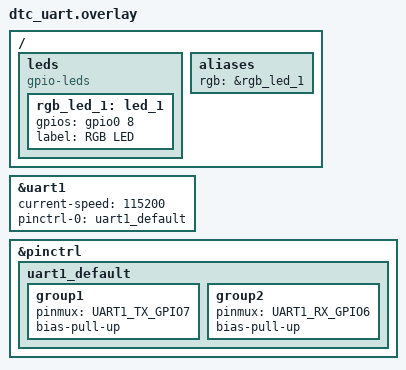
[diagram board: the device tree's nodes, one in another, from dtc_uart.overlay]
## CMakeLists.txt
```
# SPDX-License-Identifier: Apache-2.0

cmake_minimum_required(VERSION 3.20.0)
set(CONF_FILE prj.conf)
set(DTC_OVERLAY_FILE dtc_uart.overlay)

find_package(Zephyr REQUIRED HINTS $ENV{ZEPHYR_BASE})

FILE(GLOB app_sources src/*.c)
target_sources(app PRIVATE ${app_sources}
                            ./src/motordriver.c
                            ./src/rovermotor.c
                            ./src/roveruart.c
                            ./src/pos_mobile_bt.c
                            )
                            

project(Prac2)
```

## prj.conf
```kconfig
CONFIG_I2C=y


# new 
CONFIG_BT=y
#CONFIG_BT_CENTRAL=y
#CONFIG_BT_HOST_CCM=y

CONFIG_SERIAL=y
CONFIG_UART_INTERRUPT_DRIVEN=y
CONFIG_GPIO=y
CONFIG_I2C=y

CONFIG_STDOUT_CONSOLE=n
CONFIG_CBPRINTF_FP_SUPPORT=y

CONFIG_PRINTK=y
CONFIG_SHELL=y
CONFIG_LOG=y
CONFIG_INIT_STACKS=y
CONFIG_THREAD_STACK_INFO=y
CONFIG_KERNEL_SHELL=y
CONFIG_THREAD_MONITOR=y
CONFIG_BOOT_BANNER=n
CONFIG_THREAD_NAME=y
CONFIG_DEVICE_SHELL=y
CONFIG_EVENTS=y 
#CONFIG_POSIX_CLOCK=y
#CONFIG_DATE_SHELL=y
#CONFIG_THREAD_RUNTIME_STATS=y
#CONFIG_THREAD_RUNTIME_STATS_USE_TIMING_FUNCTIONS=y
#CONFIG_STATS=y
#CONFIG_STATS_SHELL=y
#CONFIG_BT_GATT_READ_MULTIPLE=y


CONFIG_NEWLIB_LIBC=y

CONFIG_SYSTEM_WORKQUEUE_STACK_SIZE=4096


#CONFIG_BT_BROADCASTER=y
#CONFIG_BT_OBSERVER=y
CONFIG_BT_GATT_CLIENT=y


# CONFIG_SETTINGS=y
# CONFIG_BT_SETTINGS=y
CONFIG_BT_DEVICE_NAME="rsatsrrast eir"
CONFIG_BT_SMP=y
#CONFIG_BT_MAX_CONN=3
CONFIG_BT_SIGNING=n
CONFIG_BT_PERIPHERAL=y
#CONFIG_BT_DIS=y
#CONFIG_BT_BAS=y
#CONFIG_BT_HRS=y
#CONFIG_BT_IAS=y
#CONFIG_BT_PRIVACY=y
```

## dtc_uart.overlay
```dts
#include <zephyr/dt-bindings/led/led.h>
/ {
	leds {
		compatible = "gpio-leds";
		rgb_led_1: led_1 {
			gpios = <&gpio0 8 GPIO_ACTIVE_HIGH>;
			label = "RGB LED";
		};
	};
	aliases {
		rgb = &rgb_led_1;
	};
};

&uart1 {
	status = "okay";
	current-speed = <115200>;
	pinctrl-0 = <&uart1_default>;
	pinctrl-names = "default";
};

&pinctrl {
	uart1_default: uart1_default {
		group1 {
			pinmux = <UART1_TX_GPIO7>;
			bias-pull-up; 
		};
		group2 {
			pinmux = <UART1_RX_GPIO6>;
			bias-pull-up;
		};
	};
};
```

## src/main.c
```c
#include <stdlib.h>

#include <zephyr/kernel.h>
#include <zephyr/logging/log.h>
#include <zephyr/device.h>
#include <zephyr/shell/shell.h>
#include <zephyr/drivers/i2c.h>
#include <zephyr/drivers/uart.h>
#include "rovermotor.h"
#include "roveruart.h"
#include "ahu_rgb.h"
#include <math.h> 
#include "pos_mobile_bt.h"
#define LOG_LEVEL 4
LOG_MODULE_REGISTER(main);

// RGB thread stack
K_THREAD_STACK_DEFINE(ahu_rgb_stack, AHU_RGB_STACK_SIZE);
struct k_thread ahu_rgb_thread_data;

//  Global to pass to shell commands. 
struct rovermotor_info motor_control_handle; 
struct roveruart_info uart_control_handle; 
const struct device* i2c_dev = DEVICE_DT_GET(DT_NODELABEL(i2c0));
const struct device* uart_dev = DEVICE_DT_GET(DT_NODELABEL(uart1));

// Helper function definition
void send_ahu_rgb(uint8_t red, uint8_t green, uint8_t blue);
void send_pos_to_bt_thread(struct k_msgq* pos_msgq, struct pos_data* position_bt) ;
void update_motor_and_rgb(
	uint8_t left_pedal, 
	uint8_t right_pedal, 
	uint8_t rudder_angle, 
	struct rovermotor_info* motor_handle);


/** 
 * Diagnostic command callback 
 */
static int rgb_cmd_callback(const struct shell* shell, size_t argc, char** argv)
{
	/* Struct to send rgb control information to the ahu rgb thread */
	struct ahu_rgb_colour colour;
	int r = atoi(argv[1]);
	int g = atoi(argv[2]);
	int b = atoi(argv[3]);

	if (r >= 0 && g >= 0 && b >= 0
			&& r < 256 && g < 256 && b < 256) {
		shell_fprintf(shell, SHELL_NORMAL,
				"writing rgb <%d,%d,%d>\n", r, g, b);
		send_ahu_rgb(r, g, b);
	} else {
		shell_fprintf(shell, SHELL_ERROR,
				"invalid rgb, 0 <= rgb values <= 255\n");
	}

	return 0;
}


/** 
 * Diagnostic command callback
 */
static int rover_cmd_cb(const struct shell* shell, size_t argc, char** argv) 
{
	int8_t vel = atoi(argv[1]); 
	int angle_percent = atoi(argv[2]); 
	float angle = ((float) (angle_percent)) / 100; 
	//LOG_INF("Commanding speed: %hhi, angle: %f", vel, angle);
	LOG_ERR("Deprecated");
	//update_motor_and_rgb(vel, angle, &motor_control_handle); 
	return 0;
}


/** 
 * Abstraction to handle setting motor turn rate and forward speed based on 
 * pedal position and 'angle' 
 */
void update_motor_and_rgb(
	uint8_t left_pedal, 
	uint8_t right_pedal, 
	uint8_t rudder_angle, 
	struct rovermotor_info* motor_handle) 
{
	// Convert 0 <= X <= 180 to -1 <= y <= +1 for rotation rate target. 
	int8_t rudder_centred_at_zero = ((int8_t) (rudder_angle)) - 90; 
	float angle_command = ((float)  (rudder_centred_at_zero)) / 90; 
	// Consider velocity forwards as difference between right and left pedal. 
	// Offset so full left pedal zero right is full reverse. 
	int8_t fwd_vel = ((int) (right_pedal) - (int) (left_pedal));
	rovermotor_send_instruction(motor_handle, angle_command, fwd_vel);

	int8_t r = fwd_vel + 127; 
	int8_t b = (255 - r);
	int8_t g = (int8_t) (angle_command * 128) + 127; 
	send_ahu_rgb(r, g, b); 
}

static int reset_angle_cmd_cb(const struct shell* shell, size_t argc, char** argv) 
{
	roveruart_reset_angle(&uart_control_handle);
	LOG_INF("Resetting angle");
	return 0;
}
#define STACKSIZE 1024
#define PRIORITY 7
#define MSG_SIZE 32
K_THREAD_DEFINE(ble_id, STACKSIZE * 4, ble_connect_main, NULL, NULL, NULL,
		PRIORITY, 0, 0);

int main(void) 
{
    //int err = bt_enable(NULL);

	/* Create a thread to control the ahu rgb led */
	k_tid_t ahu_rgb_thread_id = k_thread_create(&ahu_rgb_thread_data,
													ahu_rgb_stack,
													AHU_RGB_STACK_SIZE,
													ahu_rgb_thread,
													NULL, NULL, NULL,
													AHU_RGB_PRIORITY,
													0, K_NO_WAIT);

	rovermotor_init(0x5D, 0x5E, i2c_dev, &motor_control_handle); 
	roveruart_init(uart_dev, &uart_control_handle); 
	// LOG_INF("Initialized motor handler");

	/* Diagnostic shell commands */
	SHELL_CMD_ARG_REGISTER(
		rgb,
		NULL,
		"rgb <r> <g> <b>",
		rgb_cmd_callback,
		4,
		0
	);

	SHELL_CMD_ARG_REGISTER(
        rover,
        NULL,
        "rover [speed] [angle]: set speed and angle \n"
		"speed from -127 to 127, angle from -100 to 100 (int)",
        rover_cmd_cb,
        3,
        0
    );
	SHELL_CMD_ARG_REGISTER(
        reset_angle,
        NULL,
        "Reset angle refernce\n",
		reset_angle_cmd_cb,
        0,
        0
    );
	rover_position_info_t position;

	/* Struct to send rgb control information to the ahu rgb thread */
	struct ahu_rgb_colour rgb_colour;

	/* Struct to send position data to the bt thread */
	struct pos_data position_bt;

	/* Struct to receive control data from the bt thread */
	struct control_data control;
	int res = 0;
	k_msleep(50);
	roveruart_reset_angle(&uart_control_handle);
	while (1)
	{
		k_sleep(K_MSEC(200));
		// Does not wait for new values to publish. 
		res = roveruart_get_new_position(&uart_control_handle, &position);
		if (res) {
			// Nothing pending to send back. 
		} else {
			LOG_INF("Got position: (%hhu, %hhu)", position.x, position.y); 

			// Only send position data if we recieve it. 
			position_bt.x_pos = position.x;
			position_bt.y_pos = position.y;
			send_pos_to_bt_thread(&pos_msgq, &position_bt);
		}

        /* Check if update reference angle semaphore has been given from UART thread */
        if (!k_sem_take(&update_ref_angle_sem, K_NO_WAIT)) {
			roveruart_reset_angle(&uart_control_handle);
			LOG_INF("Resetting angle");
        }

		/* Check for control data from bt thread */
		if (!k_msgq_get(&control_msgq, &control, K_NO_WAIT)) {
			LOG_INF("Received from pedals: %d, %d, %d\n", control.pedal_left, control.pedal_right, control.rudder_angle);

			// Assumptions: 
			// -90 <= RUDDER < 90. 
			// pedal left and right fully saturate uint8_t range 0-255. 
			update_motor_and_rgb(
				control.pedal_left, 
				control.pedal_right, 
				control.rudder_angle, 
				&motor_control_handle);
		}
	}
}

/**
 * Sends position to BT thread (see: pos_mobile_bt.c) to be transmitted
 * to base node. Purges queue and does not send if queue is full. Non-blocking
 */
void send_pos_to_bt_thread(struct k_msgq* pos_msgq, struct pos_data* position_bt) 
{
	/* Send position data to bt thread */
	if (k_msgq_put(pos_msgq, position_bt, K_NO_WAIT) != 0) {
		/* Queue is full, purge it */
		k_msgq_purge(pos_msgq);
	}
}

/* Send the given rgb value to the ahu rgb led */
void send_ahu_rgb(uint8_t red, uint8_t green, uint8_t blue)
{
	/* Struct to send rgb control information to the ahu rgb thread */
	struct ahu_rgb_colour colour;
	colour.red = red;
	colour.green = green;
	colour.blue = blue;

	/* Send rgb control struct to rgb message queue */
	if (k_msgq_put(&ahu_rgb_msgq, &colour, K_NO_WAIT) != 0) {
		/* Queue is full, purge it */
		k_msgq_purge(&ahu_rgb_msgq);
	}
}
```

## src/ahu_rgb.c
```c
#include "ahu_rgb.h"

/*
Defining private macro functions to write a '1' or a '0' to
the specified gpio register and pin. Based on macros defined in ahu_rgb.h
*/
#define ONE_BIT(reg, pin) do { \
	__asm volatile (SET_HIGH \
			DELAY_T1H \
			SET_LOW \
			DELAY_T1L \
			:: \
			[out_reg] "r" (reg), \
			[gpio_pin] "i" (pin)); } while (false)

#define ZERO_BIT(reg, pin) do { \
	__asm volatile (SET_HIGH \
			DELAY_T0H \
			SET_LOW \
			DELAY_T0L \
			:: \
			[out_reg] "r" (reg), \
			[gpio_pin] "i" (pin)); } while (false)

/* colour as an uint32_t (using the first 24 bits) in the order of GRB */
#define WRITE_RGB(reg, pin, colour) do { \
	__asm__ volatile ( \
			"li t2, 0x1000000\n\t" \
			"loop_start: srli t2, t2, 1\n\t" \
			"bnez t2, bit_high\n\t" \
			"j loop_end\n\t" \
			"bit_high: and t3, %[rgb_value], t2\n\t" \
			"beqz t3, bit_low\n\t" \
			SET_HIGH DELAY_T1H SET_LOW DELAY_T1L \
			"j loop_start\n\t" \
			"bit_low: " SET_HIGH DELAY_T0H SET_LOW DELAY_T0L \
			"j loop_start\n\t" \
			"loop_end: " \
			:: \
			[out_reg] "r" (reg), \
			[gpio_pin] "i" (pin), \
			[rgb_value] "r" (colour) \
			: "t0", "t1", "t2", "t3", "memory" \
		); \
	} while (false)

/* Initialising message queue to be used by ahu rgb thread */
K_MSGQ_DEFINE(
    ahu_rgb_msgq,
    sizeof(struct ahu_rgb_colour),
    AHU_RGB_MSGQ_MAX_MSG,
    AHU_RGB_MSGQ_ALIGN
);

/* Function definition */
void send_rgb(uint8_t red, uint8_t green, uint8_t blue);


/* The devicetree node identifier for the "rgb_led" alias. */
#define RGB_LED_NODE DT_ALIAS(rgb)

/* Get GPIO pin information from devicetree */
static const struct gpio_dt_spec rgb = GPIO_DT_SPEC_GET(RGB_LED_NODE, gpios);

void ahu_rgb_thread(void *, void *, void *)
{
    /* Ensure that the GPIO pin for rgb control is ready */
	if (!gpio_is_ready_dt(&rgb)) {
		return;
	}

    /* Initialise the GPIO pin to be logic level low */
    gpio_pin_configure_dt(&rgb, GPIO_OUTPUT_INACTIVE);

	/* Ensure rgb gpio low */
	gpio_pin_set_dt(&rgb, 0);

    /* Struct to receive ahu rgb control data */
    struct ahu_rgb_colour colour;
	colour.red=0; colour.green=0; colour.blue=0;

    while (1) {
        /* Check message queue for rgb control structs */
        k_msgq_get(&ahu_rgb_msgq, &colour, K_NO_WAIT);

		send_rgb(0, 0, 0);
		send_rgb(colour.red, colour.green, colour.blue);

        /* Sleep for 500ms */
        k_msleep(500);

    }

}

/* Helper function to send rgb values to the addressable led */
void send_rgb(uint8_t red, uint8_t green, uint8_t blue)
{
	/* Retrieve gpio output register and gpio pin */
	volatile uint32_t *out_reg = (uint32_t *)RGB_GPIO_REG;
	const uint32_t gpio_pin = (uint32_t)RGB_GPIO_PIN;

	/* Create a byte array to store the rgb colour in the
		correct order (GRB) */
	uint8_t colour_buf[NUM_COLOURS];
	colour_buf[0] = green;
	colour_buf[1] = red;
	colour_buf[2] = blue;
	uint8_t *p_colour_buf = colour_buf;

	/* Disable interrupts and preemption */
	k_sched_lock();
	unsigned int key = irq_lock();

	/* Loop through three colours */
	for (int i = 0; i < NUM_COLOURS; i++) {
		
		uint32_t b = *p_colour_buf++;

		for (int32_t j = 7; j >= 0; j--) {
			if (b & BIT(j)) {
				ONE_BIT(out_reg, gpio_pin);
			} else {
				ZERO_BIT(out_reg, gpio_pin);
			}
		}

	}

	/* Re-enable interrupts and preemption */
	irq_unlock(key);
	k_sched_unlock();

    /* Reset delay to ensure LED latches */
	k_busy_wait(RGB_RESET_DELAY_US);

}
```

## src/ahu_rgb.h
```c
#ifndef AHU_RGB_H_
#define AHU_RGB_H_

#include <zephyr/kernel.h>
#include <zephyr/drivers/gpio.h>
#include <string.h>

/* Defining macros for nop assembly instructions */
#define NOP1 "nop\n\t"
#define NOP2 NOP1 NOP1
#define NOP4 NOP2 NOP2
#define NOP8 NOP4 NOP4
#define NOP16 NOP8 NOP8
#define NOP32 NOP16 NOP16
#define NOP64 NOP32 NOP32
#define NOP128 NOP64 NOP64

/*
Defining macros for the rgb delays (T0H, T1H, T0L, T0H)

Note that system clock is running at 160MHz and
each nop instruction takes one clock cycle to complete
=> each nop has a delay of 1/160Mhz = 6.25ns

Based on timings for the SK6812 RGB LED:

T0H: 300ns/6.25ns = 48 cycles = 32+16 cycles
T1H: 600ns/6.25ns = 96 cycles = 64+32 cycles
T0L: 900ns/6.25ns = 144 cycles = 128+16 cycles
T1L: 600ns/6.25ns = 96 cycles = 64+32 cycles
*/
#define DELAY_T0H NOP32 NOP16
#define DELAY_T1H NOP64 NOP32
#define DELAY_T0L NOP128 NOP16
#define DELAY_T1L NOP64 NOP32

/* Defining macros with RISC-V assembly to drive specified
   GPIOs high or low */
#define SET_HIGH 	"li t0, 1\n\t" \
					"slli t0, t0, %[gpio_pin]\n\t" \
					"lw t1, 0(%[out_reg])\n\t" \
					"or t1, t1, t0\n\t" \
					"sw t1, 0(%[out_reg])\n\t"

#define SET_LOW 	"li t0, 1\n\t" \
					"slli t0, t0, %[gpio_pin]\n\t" \
					"not t0, t0\n\t" \
					"lw t1, 0(%[out_reg])\n\t" \
					"and t1, t1, t0\n\t" \
					"sw t1, 0(%[out_reg])\n\t"

/* Defining macros for constants */
#define NUM_COLOURS 3
#define RGB_RESET_DELAY_US 80
#define RGB_GPIO_REG 0x60004004
#define RGB_GPIO_PIN 8

/* Macro definitions for ahu rgb thread */
#define AHU_RGB_STACK_SIZE 1024
#define AHU_RGB_PRIORITY 3

/* Macro definitions for ahu rgb control message queue */
#define AHU_RGB_MSGQ_MAX_MSG 10
#define AHU_RGB_MSGQ_ALIGN 4

/* Entry point to ahu rgb thread */
extern void ahu_rgb_thread(void *, void *, void *);

/* struct to control the colour of the ahu rgb */
struct ahu_rgb_colour {
    uint8_t red;
	uint8_t green;
	uint8_t blue;
};

/* Message queue for ahu rgb control */
extern struct k_msgq ahu_rgb_msgq;

#endif
```

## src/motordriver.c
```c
#include "motordriver.h"
LOG_MODULE_REGISTER(motordriver);

/**
 * initializes an instance of a driver for the Sparkfun Qwiic Motor Driver /
 * Sparkfun SCMD motor driver, on given uart device, with given device address
 * @param dev: zephyr i2c device
 * @param device_addr: i2c address of qwiic motor driver. 
 */
void motordriver_init(const struct device* dev, uint8_t device_addr) 
{

    if (!device_is_ready(dev)) {
		LOG_ERR("I2C: Device is not ready.\n");
		return;
	}
    // dummy read - check the device we expect is on this bus. 
    uint8_t res;
    int status = i2c_reg_read_byte(dev, device_addr, SCMD_ID, &res);
    int num_tries = 0; 
    while (res != ID_WORD) 
    {
        LOG_INF("Couldn't get valid ID yet ... ");
        // Keep trying - it might come online. 
        k_sleep(K_MSEC(100));
        status = i2c_reg_read_byte(dev, device_addr, SCMD_ID, &res);
        if (num_tries++ > CONN_MAX_NUM_TRIES) {
            LOG_ERR("Couldn't find driver with addr %x", device_addr);
            return; 
        };

    }
    if (status) {
        LOG_ERR("Dummy read failed");
        // The driver did not come online - ignore for now. 
    } else {
        LOG_INF("Found motor driver with id %x", res);
    }

    // Enable, check enable byte. Bridge left and right channels. 
    i2c_reg_write_byte(dev, device_addr, SCMD_DRIVER_ENABLE, 0x01);

    i2c_reg_read_byte(dev, device_addr, SCMD_DRIVER_ENABLE, &res);
    i2c_reg_write_byte(dev, device_addr, SCMD_BRIDGE, 0x01);
    
    // Zero the motors (in case the driver was left powere)
    motordriver_send_pwm(dev, device_addr, ZERO_SIGNAL); 
}


/** 
 * Sends a value for motor pwm to the motor controller with given i2c addr
 * @param dev: zephyr i2c device
 * @param device_addr: qwiic motor driver i2c address
 * @param val: value to send.
 */
int motordriver_send_pwm(const struct device* dev, uint8_t device_addr, uint8_t val)
{
    //LOG_INF("Motors: %hhu", val);
    int res = i2c_reg_write_byte(dev, device_addr, SCMD_MA_DRIVE, val);
    if (res) {
        return res;
    }
    res = i2c_reg_write_byte(dev, device_addr, SCMD_MB_DRIVE, val);
    return res;
    
}
```

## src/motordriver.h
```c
#ifndef _MOTOR_DRIVER_H_
#define _MOTOR_DRIVER_H_
#include <zephyr/logging/log.h>
#include <zephyr/device.h>
#include <zephyr/drivers/i2c.h>

// Sourced from Sparkfun SCMD driver, original header below: 
/******************************************************************************
SCMD_config.h
Serial Controlled Motor Driver
Marshall Taylor @ SparkFun Electronics
Nov 3, 2016
https://github.com/sparkfun/Serial_Controlled_Motor_Driver
https://github.com/sparkfun/SparkFun_Serial_Controlled_Motor_Driver_Arduino_Library

This file contains common names for memory locations and hardware defaults.
This is used by the PSoC firmware and with the user Arduino library for use in
conjunction with readRegister() and writeRegister().

This code is released under the [MIT License](http://opensource.org/licenses/MIT).
Please review the LICENSE.md file included with this example. If you have any questions 
or concerns with licensing, please contact techsupport@sparkfun.com.
Distributed as-is; no warranty is given.
******************************************************************************/

//defaults ( Set config in PSoC, use for reference in Arduino )   
#define ID_WORD                    0xA9  //Device ID to be programmed into memory for reads
#define START_SLAVE_ADDR           0x50  //Start address of slaves
#define MAX_SLAVE_ADDR             0x5F  //Max address of slaves
#define MASTER_LOCK_KEY            0x9B
#define USER_LOCK_KEY              0x5C
#define FIRMWARE_VERSION           0x07
#define POLL_ADDRESS               0x4A  //Address of an unasigned, ready slave
#define MAX_POLL_LIMIT             0xC8  //200

//SCMD_STATUS_1 bits
#define SCMD_ENUMERATION_BIT       0x01
#define SCMD_BUSY_BIT              0x02
#define SCMD_REM_READ_BIT          0x04
#define SCMD_REM_WRITE_BIT         0x08
#define SCMD_HW_EN_BIT             0x10
 
//SCMD_CONTROL_1 bits
#define SCMD_FULL_RESET_BIT        0x01
#define SCMD_RE_ENUMERATE_BIT      0x02
    
//SCMD_FSAFE_CTRL bits and masks
#define SCMD_FSAFE_DRIVE_KILL      0x01
#define SCMD_FSAFE_RESTART_MASK    0x06
	#define SCMD_FSAFE_REBOOT          0x02
	#define SCMD_FSAFE_RE_ENUM         0x04
#define SCMD_FSAFE_CYCLE_USER      0x08
#define SCMD_FSAFE_CYCLE_EXP       0x10

//SCMD_MST_E_IN_FN bits and masks
#define SCMD_M_IN_RESTART_MASK    0x03
	#define SCMD_M_IN_REBOOT          0x01
	#define SCMD_M_IN_RE_ENUM         0x02
#define SCMD_M_IN_CYCLE_USER      0x04
#define SCMD_M_IN_CYCLE_EXP       0x08

//Address map
#define SCMD_FID                   0x00
#define SCMD_ID                    0x01
#define SCMD_SLAVE_ADDR            0x02
#define SCMD_CONFIG_BITS           0x03
#define SCMD_U_I2C_RD_ERR          0x04
#define SCMD_U_I2C_WR_ERR          0x05
#define SCMD_U_BUF_DUMPED          0x06
#define SCMD_E_I2C_RD_ERR          0x07
#define SCMD_E_I2C_WR_ERR          0x08
#define SCMD_LOOP_TIME	           0x09
#define SCMD_SLV_POLL_CNT          0x0A
#define SCMD_SLV_TOP_ADDR          0x0B
#define SCMD_MST_E_ERR             0x0C
#define SCMD_MST_E_STATUS          0x0D
#define SCMD_FSAFE_FAULTS          0x0E
#define SCMD_REG_OOR_CNT           0x0F
#define SCMD_REG_RO_WRITE_CNT      0x10
#define SCMD_GEN_TEST_WORD         0x11
#define SCMD_MOTOR_A_INVERT        0x12
#define SCMD_MOTOR_B_INVERT        0x13
#define SCMD_BRIDGE                0x14
#define SCMD_LOCAL_MASTER_LOCK     0x15
#define SCMD_LOCAL_USER_LOCK       0x16
#define SCMD_MST_E_IN_FN           0x17
#define SCMD_U_PORT_CLKDIV_U       0x18
#define SCMD_U_PORT_CLKDIV_L       0x19
#define SCMD_U_PORT_CLKDIV_CTRL    0x1A
#define SCMD_E_PORT_CLKDIV_U       0x1B
#define SCMD_E_PORT_CLKDIV_L       0x1C
#define SCMD_E_PORT_CLKDIV_CTRL    0x1D
#define SCMD_U_BUS_UART_BAUD       0x1E
#define SCMD_FSAFE_CTRL            0x1F
#define SCMD_MA_DRIVE              0x20
#define SCMD_MB_DRIVE              0x21
#define SCMD_S1A_DRIVE             0x22
#define SCMD_S1B_DRIVE             0x23
#define SCMD_S2A_DRIVE             0x24
#define SCMD_S2B_DRIVE             0x25
#define SCMD_S3A_DRIVE             0x26
#define SCMD_S3B_DRIVE             0x27
#define SCMD_S4A_DRIVE             0x28
#define SCMD_S4B_DRIVE             0x29
#define SCMD_S5A_DRIVE             0x2A
#define SCMD_S5B_DRIVE             0x2B
#define SCMD_S6A_DRIVE             0x2C
#define SCMD_S6B_DRIVE             0x2D
#define SCMD_S7A_DRIVE             0x2E
#define SCMD_S7B_DRIVE             0x2F
#define SCMD_S8A_DRIVE             0x30
#define SCMD_S8B_DRIVE             0x31
#define SCMD_S9A_DRIVE             0x32
#define SCMD_S9B_DRIVE             0x33
#define SCMD_S10A_DRIVE            0x34
#define SCMD_S10B_DRIVE            0x35
#define SCMD_S11A_DRIVE            0x36
#define SCMD_S11B_DRIVE            0x37
#define SCMD_S12A_DRIVE            0x38
#define SCMD_S12B_DRIVE            0x39
#define SCMD_S13A_DRIVE            0x3A
#define SCMD_S13B_DRIVE            0x3B
#define SCMD_S14A_DRIVE            0x3C
#define SCMD_S14B_DRIVE            0x3D
#define SCMD_S15A_DRIVE            0x3E
#define SCMD_S15B_DRIVE            0x3F
#define SCMD_S16A_DRIVE            0x40
#define SCMD_S16B_DRIVE            0x41

#define SCMD_INV_2_9               0x50
#define SCMD_INV_10_17             0x51
#define SCMD_INV_18_25             0x52
#define SCMD_INV_26_33             0x53
#define SCMD_BRIDGE_SLV_L          0x54
#define SCMD_BRIDGE_SLV_H          0x55

#define SCMD_DRIVER_ENABLE         0x70
#define SCMD_UPDATE_RATE           0x71
#define SCMD_FORCE_UPDATE          0x72
#define SCMD_E_BUS_SPEED           0x73
#define SCMD_MASTER_LOCK           0x74
#define SCMD_USER_LOCK             0x75
#define SCMD_FSAFE_TIME            0x76
#define SCMD_STATUS_1              0x77
#define SCMD_CONTROL_1             0x78

#define SCMD_REM_ADDR              0x79
#define SCMD_REM_OFFSET            0x7A
#define SCMD_REM_DATA_WR           0x7B
#define SCMD_REM_DATA_RD           0x7C
#define SCMD_REM_WRITE             0x7D
#define SCMD_REM_READ              0x7E

#define CONN_MAX_NUM_TRIES 5

#define ZERO_SIGNAL 127 


/**
 * initializes an instance of a driver for the Sparkfun Qwiic Motor Driver /
 * Sparkfun SCMD motor driver, on given uart device, with given device address
 * @param dev: zephyr i2c device
 * @param device_addr: i2c address of qwiic motor driver. 
 */
extern void motordriver_init(const struct device* dev, uint8_t device_addr);


/** 
 * Sends a value for motor pwm to the motor controller with given i2c addr
 * @param dev: zephyr i2c device
 * @param device_addr: qwiic motor driver i2c address
 * @param val: value to send.
 */
extern int motordriver_send_pwm(const struct device* dev, uint8_t device_addr, uint8_t val); 

#endif 
```

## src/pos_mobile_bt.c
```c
#include "pos_mobile_bt.h"

#ifdef CONFIG_ARCH_POSIX
#include <unistd.h>
#else
#include <zephyr/posix/unistd.h>
#endif

/* Initialising message queue for control data */
K_MSGQ_DEFINE(
    control_msgq,
    sizeof(struct control_data),
    CONTROL_MSGQ_MAX_MSG,
    CONTROL_MSGQ_ALIGN
);

/* Initialising message queue for position data */
K_MSGQ_DEFINE(
    pos_msgq,
    sizeof(struct pos_data),
    POS_MSGQ_MAX_MSG,
    POS_MSGQ_ALIGN
);

/* Semaphore to signal refernce angle updates */
K_SEM_DEFINE(update_ref_angle_sem, 0, 1);

static struct bt_conn *default_conn;
bool bt_connected;

LOG_MODULE_REGISTER(app);

uint8_t current_cont[] = {0, 90, 0};
uint8_t pos_data[] = {0, 0};

static const struct bt_data ad[] = {
    BT_DATA_BYTES(BT_DATA_FLAGS, (BT_LE_AD_GENERAL | BT_LE_AD_NO_BREDR)),
    BT_DATA_BYTES(BT_DATA_UUID128_ALL,
                  0xd0, 0x92, 0x67, 0x35, 0x78, 0x16, 0x21, 0x91,
                  0x26, 0x49, 0x60, 0xeb, 0x06, 0xa7, 0xca, 0xcb),
};

static struct bt_uuid_128 mobile_uuid = BT_UUID_INIT_128(
    0xd0, 0x92, 0x67, 0x35, 0x78, 0x16, 0x21, 0x91,
    0x26, 0x49, 0x60, 0xeb, 0x06, 0xa7, 0xca, 0xcb);

static struct bt_uuid_128 pos_uuid = BT_UUID_INIT_128(
    0xd8, 0x92, 0x67, 0x35, 0x78, 0x16, 0x21, 0x91,
    0x26, 0x49, 0x60, 0xeb, 0x06, 0xa7, 0xca, 0xcb);

static struct bt_uuid_128 cont_uuid = BT_UUID_INIT_128(
    0xd8, 0x92, 0x67, 0x35, 0x78, 0x16, 0xa1, 0x91,
    0x26, 0x29, 0x60, 0xeb, 0x46, 0xa7, 0xca, 0xcb);

static struct bt_uuid_128 angle_uuid = BT_UUID_INIT_128(
    0xd8, 0x92, 0x67, 0x35, 0x50, 0x16, 0x21, 0x91,
    0x26, 0x49, 0x06, 0xeb, 0x06, 0xa7, 0x23, 0xcb);


static ssize_t give_pos(struct bt_conn *conn,
                          const struct bt_gatt_attr *attr, void *buf,
                          uint16_t len, uint16_t offset)
{
    const int16_t *value = attr->user_data;

    return bt_gatt_attr_read(conn, attr, buf, len, offset, value, sizeof(pos_data));
}

static ssize_t update_angle(struct bt_conn *conn,
                          const struct bt_gatt_attr *attr, void *buf,
                          uint16_t len, uint16_t offset)
{
    const int16_t *value = NULL;
    
    /* Send semaphore to main */
    k_sem_give(&update_ref_angle_sem);
    LOG_ERR("sending semaphore");

    return bt_gatt_attr_read(conn, attr, buf, len, offset, value, 0);
}

BT_GATT_SERVICE_DEFINE(mobile_svc,
                       BT_GATT_PRIMARY_SERVICE(&mobile_uuid),
                       
                       BT_GATT_CHARACTERISTIC(&pos_uuid.uuid,
                                              BT_GATT_CHRC_READ,
                                              BT_GATT_PERM_READ,
                                              give_pos, NULL, &pos_data),

                       BT_GATT_CHARACTERISTIC(&angle_uuid.uuid,
                                              BT_GATT_CHRC_READ,
                                              BT_GATT_PERM_READ,
                                              update_angle, NULL, NULL),  );


static void connected(struct bt_conn *conn, uint8_t err)
{
    if (err) {
		LOG_ERR("Connection failed (err 0x%02x)\n", err);
        bt_connected = false;
	} else {
		LOG_INF("Connected");
        bt_connected = true;
	}
    default_conn = conn;
}

static void disconnected(struct bt_conn *conn, uint8_t reason)
{
    LOG_INF("Disconnected");
	bt_connected = false;
}

static void auth_passkey_display(struct bt_conn *conn, unsigned int passkey)
{
    char addr[BT_ADDR_LE_STR_LEN];

    bt_addr_le_to_str(bt_conn_get_dst(conn), addr, sizeof(addr));

}

static void auth_cancel(struct bt_conn *conn)
{
    char addr[BT_ADDR_LE_STR_LEN];

    bt_addr_le_to_str(bt_conn_get_dst(conn), addr, sizeof(addr));
	k_msleep(50);
}

uint8_t read_cont(struct bt_conn *conn, uint8_t err,
                               struct bt_gatt_read_params *params,
                               const void *data, uint16_t length)
{
    if (length == 3 && bt_connected) {
        memcpy(&current_cont, data, 3);
        //printk("%d %d %d\n", current_cont[0], current_cont[1], current_cont[2]);
    }
    return 0;
}


static struct bt_conn_cb conn_callbacks = {
    .connected = connected,
    .disconnected = disconnected,
};

static struct bt_conn_auth_cb auth_cb_display = {
    .passkey_display = auth_passkey_display,
    .passkey_entry = NULL,
    .cancel = auth_cancel,
};

static void bt_ready(void)
{
    int err = 0;
    err = bt_enable(NULL);
    if (err)
    {
        printk("Bluetooth init failed (err %d)\n", err);
        return;
    }

    printk("Bluetooth initialized\n");
    /*
    if (IS_ENABLED(CONFIG_SETTINGS))
    {
        settings_load();
    }
    */
    err = bt_le_adv_start(BT_LE_ADV_CONN_NAME, ad, ARRAY_SIZE(ad), NULL, 0);

    if (err)
    {
        printk("Advertising failed to start (err %d)\n", err);
        return;
    }
    printk("Advertising successfully started\n");
}

void ble_connect_main(void)
{
	bt_ready();

    bt_conn_cb_register(&conn_callbacks);
    bt_conn_auth_cb_register(&auth_cb_display);

    static struct bt_gatt_read_params read_cont_params = {
        .func = read_cont,
        .handle_count = 0,
        .by_uuid.uuid = &cont_uuid.uuid,
        .by_uuid.start_handle = BT_ATT_FIRST_ATTRIBUTE_HANDLE,
        .by_uuid.end_handle = BT_ATT_LAST_ATTRIBUTE_HANDLE,
    };

    /* Struct to store all control values */
    struct control_data control;

    /* Struct to store position values */
    struct pos_data position;

    while (1)
    {
        if (bt_connected) {
            bt_gatt_read(default_conn, &read_cont_params);

            control.pedal_left = current_cont[0];
            control.pedal_right = current_cont[1];
            control.rudder_angle = current_cont[2];

            /* Send control data to main */
            //LOG_INF("Sending to main");
            if (k_msgq_put(&control_msgq, &control, K_NO_WAIT) != 0) {
                /* Queue is full, purge it */
                LOG_ERR("Purging control message queue to main. ");
                k_msgq_purge(&control_msgq);
            }

            // Check for updated pos from main
            while (!k_msgq_get(&pos_msgq, &position, K_MSEC(200))) {
                pos_data[0] = position.x_pos;
                pos_data[1] = position.y_pos;
            }

        } else {
            k_msleep(100);
        }
    }
}
```

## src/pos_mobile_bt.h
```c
#ifndef BSU_BT_H
#define BSU_BT_H

#include <zephyr/kernel.h>

#include <zephyr/types.h>

#include <zephyr/sys/printk.h>
#include <zephyr/sys/byteorder.h>
#include <zephyr/sys/util.h>

#include <zephyr/shell/shell.h>

#include <zephyr/drivers/uart.h>
#include <zephyr/drivers/gpio.h>
#include <zephyr/devicetree.h>

#include <zephyr/logging/log.h>

#include <zephyr/bluetooth/bluetooth.h>
#include <zephyr/bluetooth/hci.h>
#include <zephyr/bluetooth/conn.h>
#include <zephyr/bluetooth/uuid.h>
#include <zephyr/bluetooth/gatt.h>

#include <stddef.h>
#include <errno.h>
#include <version.h>
#include <stdlib.h>
#include <ctype.h>
#include <stdio.h>
#include <math.h>


/* Macro definitions for control message queue */
#define CONTROL_MSGQ_MAX_MSG 10
#define CONTROL_MSGQ_ALIGN 4

/* Macro definitions for position message queue */
#define POS_MSGQ_MAX_MSG 10
#define POS_MSGQ_ALIGN 4

void ble_connect_main(void);

/* Message queue for control data */
extern struct k_msgq control_msgq;

/* Message queue for position data */
extern struct k_msgq pos_msgq;

/* Struct for control data */
struct control_data {
    uint8_t pedal_left;
    uint8_t pedal_right;
    /* 0 <= RUDDER <= 180*/
    uint8_t rudder_angle;
};

/* Struct for position data */
struct pos_data {
    uint8_t x_pos;
    uint8_t y_pos;
};

/* Semaphore for signalling reference angle updates */
extern struct k_sem update_ref_angle_sem;

#endif
```

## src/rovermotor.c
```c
#include "rovermotor.h"
LOG_MODULE_REGISTER(rovermotor);

K_THREAD_STACK_DEFINE(rovermotor_handler_stack, ROVERMOTOR_STACK_SIZE);

/**
 * Initializes parameters stored in rovermotor handle motor_info. 
 * Creates handler thread and returns its thread ID. 
 * @param left_addr 7-bit i2c address of left-side motor controller
 * @param right_addr 7 bit i2c address of right side motor controller
 * @param dev zephyr i2c device that each motor driver is run on. 
 * @param motor_info uninitialized struct (it is initialized in this function). 
 */
k_tid_t rovermotor_init(
            uint8_t left_addr, 
            uint8_t right_addr, 
            const struct device* dev, 
            struct rovermotor_info* motor_info
            ) 
{
    motor_info->left_addr = left_addr;
    motor_info->right_addr = right_addr;
    motor_info->dev = dev; 
    
    k_msgq_init(
        &(motor_info->handler_queue), 
        motor_info->cmd_msg_buf, 
        sizeof(struct rover_queue_msg), 
        16
        );

    // Create thread and pass in handler struct to avoid global. 
    LOG_INF("Creating thread to handle rover motor control");
    return k_thread_create(&(motor_info->motor_thread_data), rovermotor_handler_stack,
		K_THREAD_STACK_SIZEOF(rovermotor_handler_stack),
		rovermotor_handler,
		(void*) (motor_info), NULL, NULL,
		ROVERMOTOR_PRIORITY, 0, K_NO_WAIT);
}

/**
 * Hanlder thread for rover motor control. Blocks until a message is received from 
 * another task (from call to rovermotor_send_instruction). 
 * First parameter is pointer to handler struct rovermotor_info
 */
void rovermotor_handler(void* handler, void*, void* )
{
    struct rovermotor_info info = *((struct rovermotor_info*) handler); 
    struct rover_queue_msg instruction; 
    int msg_rx_status; 
    // Initialize left and right motors. 
    LOG_INF("Initializing left motor");
    motordriver_init(info.dev, info.left_addr);
    k_msleep(10);
    LOG_INF("Initializing right motor");
    motordriver_init(info.dev, info.right_addr); 

    // Block until a message comes in, process, update motor control. 
    while (1) {
        msg_rx_status = k_msgq_get(&(info.handler_queue), (void*) (&instruction), K_FOREVER);
        if (msg_rx_status) {
            LOG_INF("Couldn't get command from queue, %i", msg_rx_status); 
        } else {
            // We have a command to instruct the motor driver. 
            // Set angular velocity - scale -100-100% (0 to 1) command
            int left = instruction.direction * ANGLE_CHANGE_RATE_CONST; 
            // Turning only - left will move at opposite speed to right
            int right = left * -1; 

            // Adjust for forward velocity - increase vel of each motor to retain turning.
            left += ((int) (instruction.velocity)) * FWD_VELOCITY_RATE_CONST;
            right += ((int) (instruction.velocity)) * FWD_VELOCITY_RATE_CONST; 
            LOG_INF("Left: %i, right: %i", left, right);

            // avoid wraparound when casting. 
            if (left > 127) {
                left = 127; 
            } else if (left < -128) {
                left = -128; 
            }

            if (right > 127) {
                right = 127; 
            } else if (right < -128) {
                right = -128; 
            }
            // Map int8 range to 0-255 for motor drive. 
            uint8_t left_motor_cmd = left + 127; 
            uint8_t right_motor_cmd = right + 127; 

            // Control each motor. 
            motordriver_send_pwm(info.dev, info.left_addr, left_motor_cmd);
            motordriver_send_pwm(info.dev, info.right_addr, right_motor_cmd); 
        }
    }
    
}

/**
 * Sends instruction to rover motor control handler thread, to move rover 
 * forward at given speed, and to turn at given direction speed
 * @require direction if from -1 to 1, mapping angular velocity (like a percentage). 
 */
int rovermotor_send_instruction(
        struct rovermotor_info* motor_info, 
        float direction, 
        int8_t speed) 
{
    struct rover_queue_msg command = {
        .direction = direction,
        .velocity = speed,
    };
    // Send across to thread. Don't wait to avoid blocking caller task. 
    int status = k_msgq_put(&(motor_info->handler_queue), (void*) (&command), K_NO_WAIT);
    if (status == -ENOMSG) {
        LOG_ERR("Couldn't send to handler: ENOMSG: Returned without waiting or queue purged.");
    } else if (status == -EAGAIN) {
        LOG_ERR("Couldn't send to handler: EAGAIN: Waiting period timed out.");
    } else if (status) {
        LOG_ERR("Couldn't send to handler: unknown error");
    }
    return status; 
}
```

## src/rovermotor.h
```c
#ifndef _ROVERMOTOR_H_
#define _ROVERMOTOR_H_
#include <stdlib.h>
#include <zephyr/kernel.h>
#define ROVERMOTOR_STACK_SIZE 4096
#define ROVERMOTOR_PRIORITY 14
#define FWD_VELOCITY_RATE_CONST 1
#define ANGLE_CHANGE_RATE_CONST 80
#define LOG_LEVEL 4
#include <zephyr/logging/log.h>
#include <zephyr/device.h>
#include "motordriver.h"


/** 
 * Handler to store control information on rover
 * motor control. 
 */
struct rovermotor_info 
{
    /* i2c addr of left motor controller */
    uint8_t left_addr;
    /* i2c addr of right motor controller */
    uint8_t right_addr;
    /* queue for instructions to drive motors*/
    struct k_msgq handler_queue;
    /* internal */
    char __aligned(4) cmd_msg_buf[16 * sizeof(float)];
    /* i2c periperhal device */
    const struct device* dev; 
    /* thread performing motor control */
    struct k_thread motor_thread_data; 
};


/* Single message to send to motors. */
struct rover_queue_msg 
{
    /* Mapping -1 to +1 for maximum left turn rate 
    * to maximum right turn rate. */
    float direction;
    /* Velocity in forward direction */
    int8_t velocity; 
};


/**
 * Initializes parameters stored in rovermotor handle motor_info. 
 * Creates handler thread and returns its thread ID. 
 * @param left_addr 7-bit i2c address of left-side motor controller
 * @param right_addr 7 bit i2c address of right side motor controller
 * @param dev zephyr i2c device that each motor driver is run on. 
 * @param motor_info uninitialized struct (it is initialized in this function). 
 */
extern k_tid_t rovermotor_init (
            uint8_t left_addr, 
            uint8_t right_addr, 
            const struct device* dev, 
            struct rovermotor_info* motor_info
            );


/**
 * Sends instruction to rover motor control handler thread, to move rover 
 * forward at given speed, and to turn at given direction speed
 * @require direction if from -1 to 1, mapping angular velocity (like a percentage). 
 */
extern int rovermotor_send_instruction(
        struct rovermotor_info* motor_info, 
        float direction, 
        int8_t speed);
        

/**
 * Hanlder thread for rover motor control. Blocks until a message is received from 
 * another task (from call to rovermotor_send_instruction). 
 * First parameter is pointer to handler struct rovermotor_info
 */
void rovermotor_handler(void* handler, void*, void* );

#endif 
```

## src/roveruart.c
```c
#include "roveruart.h"

LOG_MODULE_REGISTER(roveruart);


/** 
 * Initializes uart communications with disco. 
 * Uart is handled interrupt based, with configuration 
 * data stored in handler struct to avoid global variables. 
 * @param dev: zephyr uart device 
 * @param info: empty, to be populated 
 */
int roveruart_init(const struct device* dev, struct roveruart_info* info) 
{
	if (!device_is_ready(dev)) {
		LOG_ERR("UART: Device is not ready.\n");
		return -1;
	}

	/* Create queue with handler and buffer stored in hanlder struct. */
	k_msgq_init(&(info->receive), &(info->receive_buf[0]), sizeof(rover_position_info_t), 10);

	/* Enable uart character ISR. Send handler struct to callback. */
    int ret = uart_irq_callback_user_data_set(dev, roveruart_rx_cb, (void*) info);
	uart_irq_rx_enable(dev);
	info->dev = dev;
	return ret; 
}


/**
 * Callback for when a character is received over uart. 
 */
void roveruart_rx_cb(const struct device* dev, void* user_data) 
{	
	struct roveruart_info* info = ((struct roveruart_info*) user_data);
	uint8_t rxd;
	static int num_rxd = 0; 
	rover_position_info_t pos; 
	// Update our uart IRQ, and make sure it's ready to avoid spurious calls. 
	if (!uart_irq_update(dev)) {
		return;
	}

	if (!uart_irq_rx_ready(dev)) {
		return;
	}

	// Read each char from the fifo and process. 
	while (uart_fifo_read(dev, &rxd, 1) == 1) {
		if (rxd == MSG_PREAMBLE) {
			// Preamble byte
			num_rxd = 1; 
		} else if (num_rxd == 1) {
			// first byte - x position
			pos.x = rxd;
			num_rxd++; 
		} else if (num_rxd > 1){
			// Last byte, update y and put in queue for main to process. 
			pos.y = rxd; 
			num_rxd = 0;
			k_msgq_put(&info->receive, &pos, K_NO_WAIT);
		}

	}
}


/** 
 * Sends command over UART to reset the angle reference of the disco
 * @param info: handler struct
 */
// Realistically this should run more than quick enough to not need threading. 
void roveruart_reset_angle(struct roveruart_info* info) 
{
	LOG_INF("Resetting angle");
	uart_poll_out(info->dev, 0x69);
}


/**
 * Returns -EAGAIN if no message is waiting in queue, -ENOMSG if other failure, 
 * otherwsie populates pos struct pointer with values. 
 * @param info: handler struct 
 * @param pos: empty struct to populate in this call. 
 */
int roveruart_get_new_position(
		struct roveruart_info* info, 
		rover_position_info_t* pos) 
{
	int res = k_msgq_get(&(info->receive), (void*) pos, K_NO_WAIT);
	return res; 
}
```

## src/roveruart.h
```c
#ifndef _ROVERUART_H_
#define _ROVERUART_H_
#include <zephyr/logging/log.h>
#include <zephyr/device.h>
#include <zephyr/kernel.h>
#include <zephyr/drivers/uart.h>

#define LOG_LEVEL 4
#define MSG_PREAMBLE 0xFF
#define MSG_RESET_ANGLE 0x69
typedef uint8_t roveruart_transmit_t;

typedef struct rover_position_info_t {
    uint8_t x; 
    uint8_t y; 
} rover_position_info_t;

struct roveruart_info {
    /* UNUSED */ 
    struct k_msgq transmit; 
    /* UNUSED */
    char __aligned(4) transmit_buf[10 * sizeof(roveruart_transmit_t)];
    /* Contains each full message received from disco over uart */
    struct k_msgq receive; 
    /* Buffer for values contained in receive queue. */
    char __aligned(4) receive_buf[10 * sizeof(rover_position_info_t)];
    /* zephyr uart device instance */
    const struct device* dev;
};


/** 
 * Initializes uart communications with disco. 
 * Uart is handled interrupt based, with configuration 
 * data stored in handler struct to avoid global variables. 
 * @param dev: zephyr uart device 
 * @param info: empty, to be populated 
 */
extern int roveruart_init(const struct device* dev, struct roveruart_info* info);
void roveruart_rx_cb(const struct device* dev, void* user_data);


/**
 * Returns -EAGAIN if no message is waiting in queue, -ENOMSG if other failure, 
 * otherwsie populates pos struct pointer with values. 
 * @param info: handler struct 
 * @param pos: empty struct to populate in this call. 
 */
extern int roveruart_get_new_position(
		struct roveruart_info* info, 
		struct rover_position_info_t* pos);


/** 
 * Sends command over UART to reset the angle reference of the disco
 * @param info: handler struct
 */
extern void roveruart_reset_angle(struct roveruart_info* info);

#endif 
```
